VERSION ""

NS_ :

BS_:

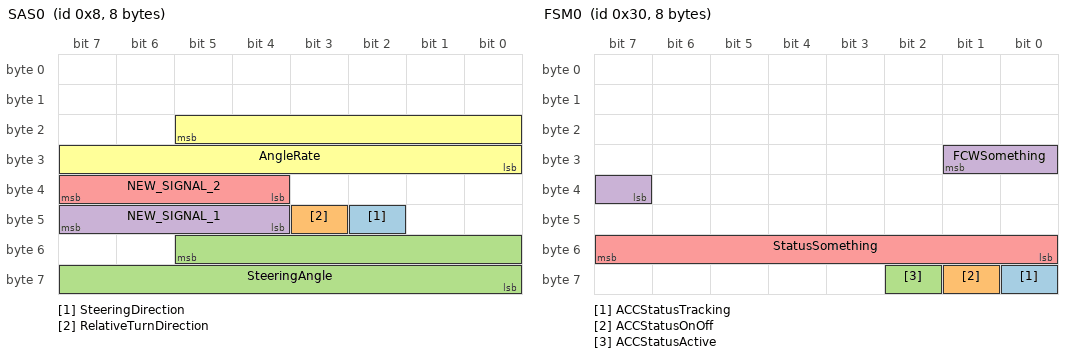
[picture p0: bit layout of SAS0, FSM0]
BO_ 8 SAS0: 8 SAS
 SG_ SteeringDirection : 42|1@0+ (1,0) [0|1] "" XXX
 SG_ RelativeTurnDirection : 43|1@0+ (1,0) [0|1] "" XXX
 SG_ SteeringAngle : 53|14@0+ (0.04395,0) [0|65535] "degrees" XXX
 SG_ NEW_SIGNAL_1 : 47|4@0+ (1,0) [0|15] "" XXX
 SG_ NEW_SIGNAL_2 : 39|4@0+ (1,0) [0|15] "" XXX
 SG_ AngleRate : 21|14@0+ (0.075,0) [0|1500] "deg/S" XXX

BO_ 16 CCButtons: 8 CEM
 SG_ byte0 : 7|8@0+ (1,0) [0|255] "" XXX
 SG_ byte1 : 15|8@0+ (1,0) [0|255] "" XXX
 SG_ byte2 : 23|8@0+ (1,0) [0|255] "" XXX
 SG_ byte3 : 31|8@0+ (1,0) [0|255] "" XXX
 SG_ byte4 : 39|8@0+ (1,0) [0|255] "" XXX
 SG_ byte6 : 55|5@0+ (1,0) [0|31] "" XXX
 SG_ B7b0 : 56|1@0+ (1,0) [0|1] "" XXX
 SG_ B7b1 : 57|1@0+ (1,0) [0|1] "" XXX
 SG_ B7b6 : 62|1@0+ (1,0) [0|1] "" XXX
 SG_ ACCOnOffBtn : 58|1@0+ (1,0) [0|1] "" XXX
 SG_ ACCSetBtn : 63|1@0+ (1,0) [0|1] "" XXX
 SG_ ACCStopBtn : 60|1@0+ (1,0) [0|1] "" XXX
 SG_ ACCResumeBtn : 61|1@0+ (1,0) [0|1] "" XXX
 SG_ ACCMinusBtn : 48|1@0+ (1,0) [0|1] "" XXX
 SG_ TimeGapIncreaseBtn : 49|1@0+ (1,0) [0|1] "" XXX
 SG_ TimeGapDecreaseBtn : 50|1@0+ (1,0) [0|1] "" XXX
 SG_ byte5 : 47|8@0+ (1,0) [0|255] "" XXX
 SG_ B7b3 : 59|1@0+ (1,0) [0|1] "" XXX

BO_ 48 FSM0: 8 FSM
 SG_ ACCStatusTracking : 56|1@0+ (1,0) [0|1] "" XXX
 SG_ ACCStatusOnOff : 57|1@0+ (1,0) [0|1] "" XXX
 SG_ ACCStatusActive : 58|1@0+ (1,0) [0|1] "" XXX
 SG_ FCWSomething : 25|3@0+ (1,0) [0|3] "" XXX
 SG_ StatusSomething : 55|8@0+ (1,0) [0|255] "" XXX

BO_ 64 TCM0: 8 TCM
 SG_ RPMSomething : 42|11@0+ (1,0) [0|2047] "" XXX
 SG_ GearShifter : 46|2@0+ (1,0) [0|3] "" XXX

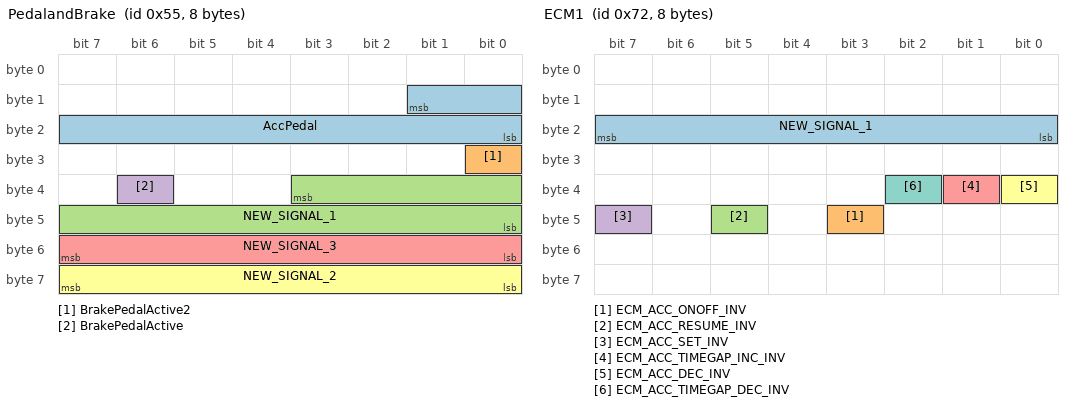
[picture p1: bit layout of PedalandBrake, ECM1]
BO_ 85 PedalandBrake: 8 ECM
 SG_ AccPedal : 9|10@0+ (0.1,0) [0|1023] "%" XXX
 SG_ BrakePedalActive2 : 24|1@0+ (1,0) [0|1] "" XXX
 SG_ NEW_SIGNAL_1 : 35|12@0+ (1,0) [0|4095] "" XXX
 SG_ BrakePedalActive : 38|1@0+ (1,0) [0|1] "" XXX
 SG_ NEW_SIGNAL_3 : 55|8@0+ (1,0) [0|255] "" XXX
 SG_ NEW_SIGNAL_2 : 63|8@0+ (1,0) [0|255] "" XXX

BO_ 101 EngineInfo: 8 XXX
 SG_ NEW_SIGNAL_1 : 17|10@0+ (1,-512) [0|1023] "" XXX
 SG_ EngineSpeed : 52|13@0+ (1,0) [0|1023] "" XXX

BO_ 112 NEW_MSG_4: 8 XXX
 SG_ NEW_SIGNAL_1 : 39|8@0+ (1,0) [0|255] "" XXX

BO_ 114 ECM1: 8 ECM1
 SG_ NEW_SIGNAL_1 : 23|8@0+ (1,0) [0|255] "" XXX
 SG_ ECM_ACC_ONOFF_INV : 43|1@0+ (1,0) [0|1] "" XXX
 SG_ ECM_ACC_RESUME_INV : 45|1@0+ (1,0) [0|1] "" XXX
 SG_ ECM_ACC_SET_INV : 47|1@0+ (1,0) [0|1] "" XXX
 SG_ ECM_ACC_TIMEGAP_INC_INV : 33|1@0+ (1,0) [0|1] "" XXX
 SG_ ECM_ACC_DEC_INV : 32|1@0+ (1,0) [0|1] "" XXX
 SG_ ECM_ACC_TIMEGAP_DEC_INV : 34|1@0+ (1,0) [0|1] "" XXX

BO_ 117 ECM1_2: 8 ECM

BO_ 128 NEW_MSG_5: 8 XXX
 SG_ NEW_SIGNAL_2 : 26|11@0+ (1,0) [0|2047] "" XXX
 SG_ NEW_SIGNAL_1 : 52|13@0+ (1,0) [0|8191] "" XXX

BO_ 176 ECM2: 8 ECM
 SG_ NEW_SIGNAL_1 : 50|11@0+ (1,0) [0|2047] "" XXX
 SG_ NEW_SIGNAL_2 : 47|8@0+ (1,0) [0|63] "" XXX

BO_ 192 Gear: 8 XXX
 SG_ TransmissionGear : 36|3@0+ (1,1) [0|7] "" XXX

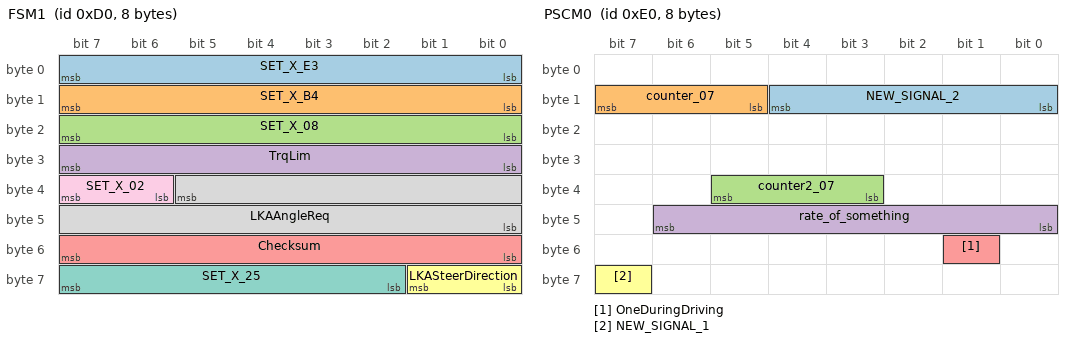
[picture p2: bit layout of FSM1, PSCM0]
BO_ 208 FSM1: 8 FSM
 SG_ SET_X_E3 : 7|8@0+ (1,0) [0|255] "" XXX
 SG_ SET_X_B4 : 15|8@0+ (1,0) [0|255] "" XXX
 SG_ SET_X_08 : 23|8@0+ (1,0) [0|255] "" XXX
 SG_ TrqLim : 31|8@0+ (1,-128) [0|255] "" XXX
 SG_ Checksum : 55|8@0+ (1,0) [0|255] "" XXX
 SG_ LKASteerDirection : 57|2@0+ (1,0) [0|2] "" XXX
 SG_ SET_X_25 : 63|6@0+ (1,0) [0|63] "" XXX
 SG_ LKAAngleReq : 37|14@0+ (0.04395,-360.0384) [-360.0384|359.99445] "degrees" XXX
 SG_ SET_X_02 : 39|2@0+ (1,0) [0|3] "" XXX

BO_ 224 PSCM0: 8 PSCM
 SG_ NEW_SIGNAL_2 : 12|5@0+ (1,0) [0|31] "" XXX
 SG_ counter_07 : 15|3@0+ (1,0) [0|7] "" XXX
 SG_ counter2_07 : 37|3@0+ (1,0) [0|16383] "" XXX
 SG_ rate_of_something : 46|7@0+ (1,0) [0|62] "" XXX
 SG_ OneDuringDriving : 49|1@0+ (1,0) [0|1] "" XXX
 SG_ NEW_SIGNAL_1 : 63|1@0+ (1,0) [0|1] "" XXX

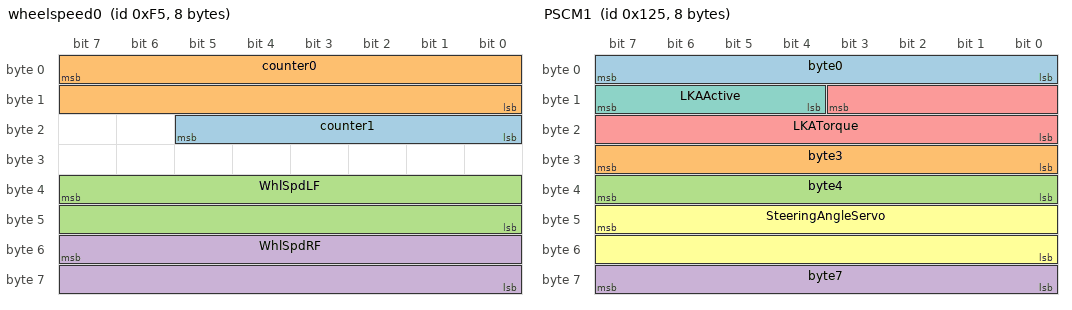
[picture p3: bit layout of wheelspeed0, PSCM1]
BO_ 245 wheelspeed0: 8 BCM
 SG_ counter1 : 21|6@0+ (1,0) [0|65535] "" XXX
 SG_ counter0 : 7|16@0+ (1,0) [0|65535] "" XXX
 SG_ WhlSpdLF : 39|16@0+ (1,0) [0|65535] "" XXX
 SG_ WhlSpdRF : 55|16@0+ (1,0) [0|65535] "" XXX

BO_ 272 SpeedSignal0: 8 XXX
 SG_ VehicleSpeedSignal : 55|16@0+ (0.01,0) [0|65535] "" XXX

BO_ 288 wheel_speed1: 8 BCM
 SG_ WhlSpdLR : 39|16@0+ (1,0) [0|65535] "" XXX
 SG_ WhlSpdRR : 55|16@0+ (1,0) [0|65535] "" XXX

BO_ 293 PSCM1: 8 PSCM
 SG_ byte0 : 7|8@0+ (1,0) [0|255] "" XXX
 SG_ byte3 : 31|8@0+ (1,0) [0|255] "" XXX
 SG_ byte4 : 39|8@0+ (1,0) [0|255] "" XXX
 SG_ byte7 : 63|8@0+ (1,0) [0|255] "" XXX
 SG_ LKATorque : 11|12@0+ (1,-2000) [0|4095] "" XXX
 SG_ SteeringAngleServo : 47|16@0+ (0.04395,-1440.1536) [0|65535] "deg" XXX
 SG_ LKAActive : 15|4@0+ (1,0) [0|15] "" XXX

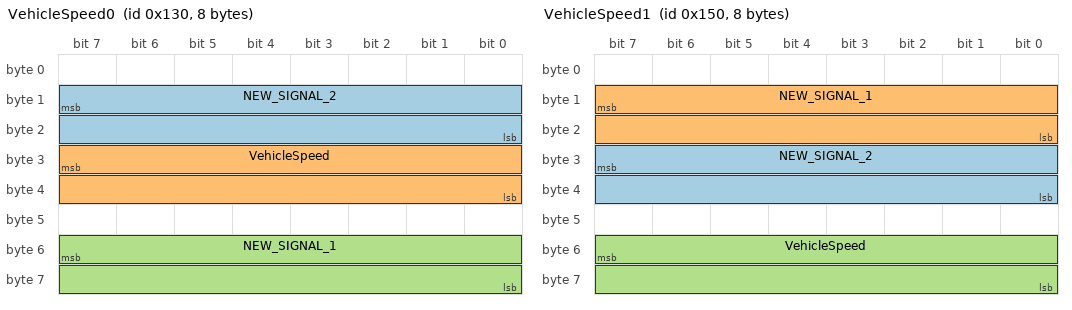
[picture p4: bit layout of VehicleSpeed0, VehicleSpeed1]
BO_ 304 VehicleSpeed0: 8 BCM
 SG_ NEW_SIGNAL_2 : 15|16@0+ (1,0) [0|65535] "" XXX
 SG_ VehicleSpeed : 31|16@0+ (0.01,0) [0|65535] "km/h" XXX
 SG_ NEW_SIGNAL_1 : 55|16@0+ (1,0) [0|65535] "" XXX

BO_ 325 ECM3: 8 ECM

BO_ 336 VehicleSpeed1: 8 BCM
 SG_ NEW_SIGNAL_2 : 31|16@0+ (1,0) [0|65535] "" XXX
 SG_ NEW_SIGNAL_1 : 15|16@0+ (1,0) [0|65535] "" XXX
 SG_ VehicleSpeed : 55|16@0+ (0.01,0) [0|65535] "" XXX

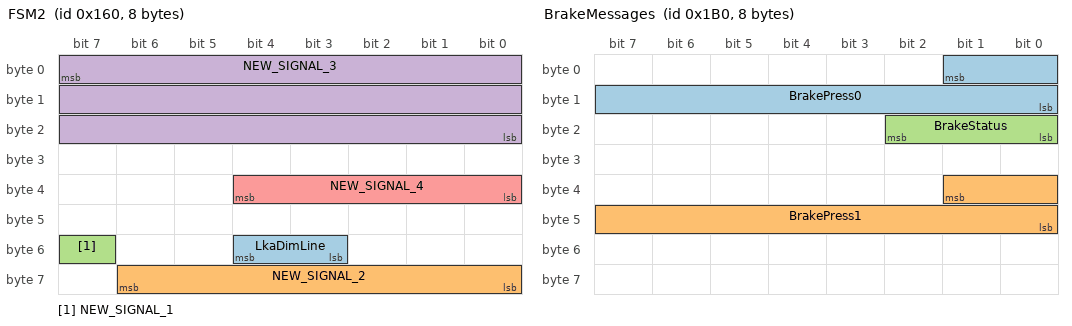
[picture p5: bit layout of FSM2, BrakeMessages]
BO_ 352 FSM2: 8 FSM
 SG_ LkaDimLine : 51|2@1+ (1,0) [0|127] "" XXX
 SG_ NEW_SIGNAL_2 : 56|7@1+ (1,0) [0|255] "" XXX
 SG_ NEW_SIGNAL_1 : 55|1@0+ (1,0) [0|1] "" XXX
 SG_ NEW_SIGNAL_3 : 7|24@0+ (1,0) [0|16777215] "" XXX
 SG_ NEW_SIGNAL_4 : 36|5@0+ (1,0) [0|31] "" XXX

BO_ 432 BrakeMessages: 8 BCM
 SG_ BrakePress0 : 1|10@0+ (1,0) [0|1023] "" XXX
 SG_ BrakePress1 : 33|10@0+ (1,0) [0|1023] "" XXX
 SG_ BrakeStatus : 18|3@0+ (1,0) [0|7] "" XXX

BO_ 464 DIM0: 8 DIM

BO_ 480 BCM0: 8 BCM

BO_ 528 CEM0: 8 CEM

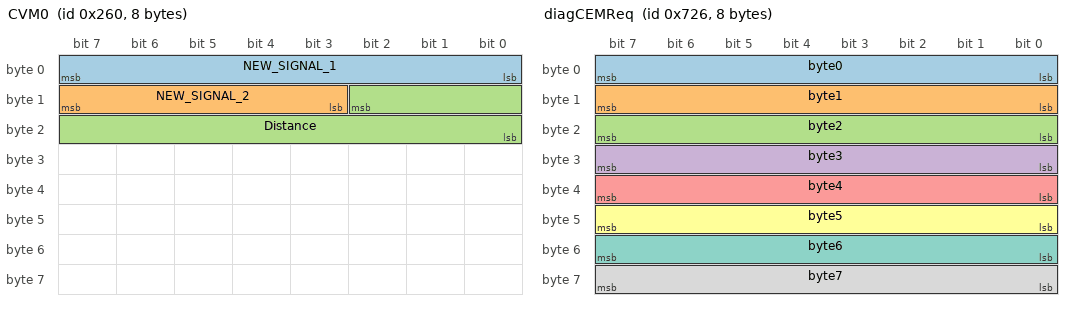
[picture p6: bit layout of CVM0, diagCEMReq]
BO_ 608 CVM0: 8 CVM
 SG_ NEW_SIGNAL_1 : 7|8@0+ (1,0) [0|255] "" XXX
 SG_ NEW_SIGNAL_2 : 15|5@0+ (1,0) [0|32] "" XXX
 SG_ Distance : 10|11@0+ (1,0) [0|2048] "" XXX

BO_ 624 FSM3: 8 FSM
 SG_ NEW_SIGNAL_1 : 23|8@0+ (1,0) [0|255] "" XXX

BO_ 640 FSM4: 8 FSM
 SG_ SpeedTarget : 47|8@0+ (1,0) [0|255] "" XXX
 SG_ NEW_SIGNAL_1 : 49|10@0+ (1,0) [0|255] "" XXX

BO_ 648 SRS0: 8 SRS

BO_ 652 ECM4: 8 ECM

BO_ 656 ECM5: 8 ECM

BO_ 657 ECM6: 8 ECM

BO_ 681 MiscCarInfo: 8 CEM
 SG_ TurnSignal : 1|2@0+ (1,0) [0|3] "" XXX
 SG_ HighBeamOn : 52|1@0+ (1,0) [0|1] "" XX

BO_ 693 ECM7: 8 ECM

BO_ 709 ACC: 8 ECM
 SG_ SpeedTargetACC : 0|9@0+ (0.5,0) [0|511] "" XXX

BO_ 853 FSM5: 8 FSM
 SG_ TargetSpeedOdo : 23|8@0+ (1,0) [0|63] "kph" XXX
 SG_ SpeedSign : 36|5@0+ (5,0) [0|32] "" XXX
 SG_ TextUnderSign : 37|1@0+ (1,0) [0|1] "" XXX
 SG_ NEW_SIGNAL_6 : 39|3@0+ (1,0) [0|3] "" XXX
 SG_ NEW_SIGNAL_5 : 47|8@0+ (1,0) [0|255] "" XXX
 SG_ NEW_SIGNAL_3 : 31|8@0+ (1,0) [0|255] "" XXX
 SG_ LaneMarkingsOdo : 15|4@0+ (1,0) [0|7] "" XXX
 SG_ NEW_SIGNAL_2 : 11|4@0+ (1,0) [0|15] "" XXX
 SG_ NEW_SIGNAL_1 : 7|8@0+ (1,0) [0|255] "" XXX
 SG_ NEW_SIGNAL_4 : 55|16@0+ (1,0) [0|65535] "" XXX

BO_ 864 CEM1: 8 CEM

BO_ 912 DIM1: 8 DIM

BO_ 968 SRS1: 8 SRS
 SG_ PassengerSeatBelt : 22|1@0+ (1,0) [0|1] "" XXX
 SG_ DriverSeatBelt : 19|1@0+ (1,0) [0|1] "" XXX

BO_ 1029 CEMBCM0: 8 CEM

BO_ 1344 NEW_MSG_1: 8 XXX
 SG_ NEW_SIGNAL_1 : 4|13@0+ (1,0) [0|8191] "" XXX

BO_ 1830 diagCEMReq: 8 XXX
 SG_ byte0 : 7|8@0+ (1,0) [0|255] "" XXX
 SG_ byte1 : 15|8@0+ (1,0) [0|255] "" XXX
 SG_ byte2 : 23|8@0+ (1,0) [0|255] "" XXX
 SG_ byte3 : 31|8@0+ (1,0) [0|255] "" XXX
 SG_ byte4 : 39|8@0+ (1,0) [0|255] "" XXX
 SG_ byte5 : 47|8@0+ (1,0) [0|255] "" XXX
 SG_ byte6 : 55|8@0+ (1,0) [0|255] "" XXX
 SG_ byte7 : 63|8@0+ (1,0) [0|255] "" XXX

BO_ 1838 diagCEMResp: 8 XXX
 SG_ byte03 : 7|32@0+ (1,0) [0|4294967295] "" XXX
 SG_ byte47 : 39|32@0+ (1,0) [0|4294967295] "" XXX

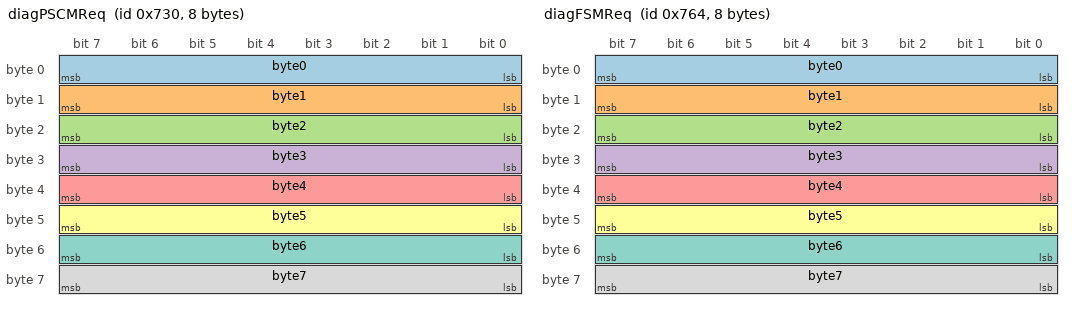
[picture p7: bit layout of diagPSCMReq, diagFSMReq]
BO_ 1840 diagPSCMReq: 8 XXX
 SG_ byte0 : 7|8@0+ (1,0) [0|255] "" XXX
 SG_ byte1 : 15|8@0+ (1,0) [0|255] "" XXX
 SG_ byte2 : 23|8@0+ (1,0) [0|255] "" XXX
 SG_ byte3 : 31|8@0+ (1,0) [0|255] "" XXX
 SG_ byte4 : 39|8@0+ (1,0) [0|255] "" XXX
 SG_ byte5 : 47|8@0+ (1,0) [0|255] "" XXX
 SG_ byte6 : 55|8@0+ (1,0) [0|255] "" XXX
 SG_ byte7 : 63|8@0+ (1,0) [0|255] "" XXX

BO_ 1848 diagPSCMResp: 8 XXX
 SG_ byte03 : 7|32@0+ (1,0) [0|4294967295] "" XXX
 SG_ byte47 : 39|32@0+ (1,0) [0|4294967295] "" XXX

BO_ 1892 diagFSMReq: 8 XXX
 SG_ byte0 : 7|8@0+ (1,0) [0|255] "" XXX
 SG_ byte1 : 15|8@0+ (1,0) [0|255] "" XXX
 SG_ byte2 : 23|8@0+ (1,0) [0|255] "" XXX
 SG_ byte3 : 31|8@0+ (1,0) [0|255] "" XXX
 SG_ byte4 : 39|8@0+ (1,0) [0|255] "" XXX
 SG_ byte5 : 47|8@0+ (1,0) [0|255] "" XXX
 SG_ byte6 : 55|8@0+ (1,0) [0|255] "" XXX
 SG_ byte7 : 63|8@0+ (1,0) [0|255] "" XXX

BO_ 1900 diagFSMResp: 8 XXX
 SG_ byte03 : 7|32@0+ (1,0) [0|4294967295] "" XXX
 SG_ byte47 : 39|32@0+ (1,0) [0|4294967295] "" XXX

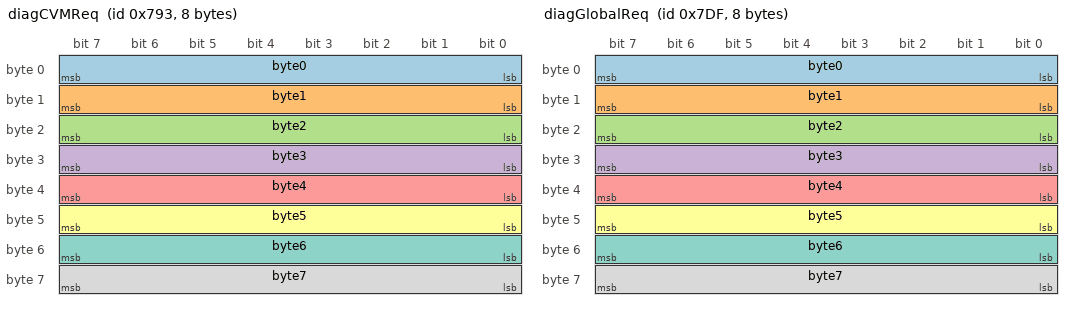
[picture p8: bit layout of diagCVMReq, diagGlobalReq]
BO_ 1939 diagCVMReq: 8 XXX
 SG_ byte0 : 7|8@0+ (1,0) [0|255] "" XXX
 SG_ byte1 : 15|8@0+ (1,0) [0|255] "" XXX
 SG_ byte2 : 23|8@0+ (1,0) [0|255] "" XXX
 SG_ byte3 : 31|8@0+ (1,0) [0|255] "" XXX
 SG_ byte4 : 39|8@0+ (1,0) [0|255] "" XXX
 SG_ byte5 : 47|8@0+ (1,0) [0|255] "" XXX
 SG_ byte6 : 55|8@0+ (1,0) [0|255] "" XXX
 SG_ byte7 : 63|8@0+ (1,0) [0|255] "" XXX

BO_ 1947 diagCVMResp: 8 XXX
 SG_ byte03 : 7|32@0+ (1,0) [0|4294967295] "" XXX
 SG_ byte47 : 39|32@0+ (1,0) [0|4294967295] "" XXX

BO_ 2015 diagGlobalReq: 8 XXX
 SG_ byte0 : 7|8@0+ (1,0) [0|255] "" XXX
 SG_ byte1 : 15|8@0+ (1,0) [0|255] "" XXX
 SG_ byte2 : 23|8@0+ (1,0) [0|255] "" XXX
 SG_ byte3 : 31|8@0+ (1,0) [0|255] "" XXX
 SG_ byte4 : 39|8@0+ (1,0) [0|255] "" XXX
 SG_ byte5 : 47|8@0+ (1,0) [0|255] "" XXX
 SG_ byte6 : 55|8@0+ (1,0) [0|255] "" XXX
 SG_ byte7 : 63|8@0+ (1,0) [0|255] "" XXX

BU_: K109_FCM B233B_LRR NEO VIS_FO VIS2_FO K124_ASCM Vector__XXX EOCM_F_FO EOCM2A_IMX6_FO EOCM2A_K2_FO EOCM2A_K1_FO EOCM2B_IMX6_FO EOCM2B_K2_FO EOCM2B_K1_FO
VAL_TABLE_ RangeMode 1 "Active" 0 "Inactive" ;
VAL_TABLE_ TrkConf 3 "Confident" 2 "Speculative" 1 "Highly speculative" 0 "Invalid" ;
VAL_TABLE_ TrkMeasStatus 3 "Measured current cycle" 2 "Latent track not detected" 1 "New object" 0 "No object" ;
VAL_TABLE_ TrkDynProp 4 "Moving in opposite direction" 3 "Moving in same direction" 2 "Has moved but currently stopped" 1 "Has never moved," 0 "Unknown" ;
VAL_TABLE_ FrntVsnInPthVehBrkNwSt 10 "Active" 5 "Inactive" ;
VAL_TABLE_ FrntVsnClostPedBrkNwSt 10 "Active" 5 "Inactive" ;
VAL_TABLE_ LaneSnsLLnPosValid 1 "Invalid" 0 "Valid" ;
VAL_TABLE_ LnSnsRLnPosValid 1 "Invalid" 0 "Valid" ;
VAL_TABLE_ ObjectType 7 "no object present" 6 "fixed roadside object" 5 "fixed overhead object" 4 "pedestrian" 3 "motocycle  / bicycle" 2 "Large vehicle (semi)" 1 "4 Wheel Vehicle (car, small trk)" 0 "Unknown" ;
VAL_TABLE_ FwVsnCinCoutPotT9Rev 2 "Right" 1 "Left" 0 "None" ;
VAL_TABLE_ FwVsnCinCoutPotT8Rev 2 "Right" 1 "Left" 0 "None" ;
VAL_TABLE_ FwVsnCinCoutPotT7Rev 2 "Right" 1 "Left" 0 "None" ;
VAL_TABLE_ FwVsnCinCoutPotT6Rev 2 "Right" 1 "Left" 0 "None" ;
VAL_TABLE_ FwVsnCinCoutPotT5Rev 2 "Right" 1 "Left" 0 "None" ;
VAL_TABLE_ FwVsnCinCoutPotT4Rev 2 "Right" 1 "Left" 0 "None" ;
VAL_TABLE_ FwVsnCinCoutPotT3Rev 2 "Right" 1 "Left" 0 "None" ;
VAL_TABLE_ FwVsnCinCoutPotT2Rev 2 "Right" 1 "Left" 0 "None" ;
VAL_TABLE_ FwVsnCinCoutPotT1Rev 2 "Right" 1 "Left" 0 "None" ;
VAL_TABLE_ FwVsnCinCoutPotT12Rev 2 "Right" 1 "Left" 0 "None" ;
VAL_TABLE_ FwVsnCinCoutPotT11Rev 2 "Right" 1 "Left" 0 "None" ;
VAL_TABLE_ FwVsnCinCoutPotT10Rev 2 "Right" 1 "Left" 0 "None" ;

CM_ BU_ K182_PACM "Parking Assist Control Module";
CM_ BU_ K43_PSCM "Power Steering Control Module";
CM_ BU_ K17_EBCM "Electronic Brake Control Module";
CM_ BU_ NEO "Comma NEO";
CM_ BU_ K124_ASCM "Active Safety Control Module";
BA_DEF_  "UseGMParameterIDs" INT 0 0;
BA_DEF_  "ProtocolType" STRING ;
BA_DEF_  "BusType" STRING ;
BA_DEF_DEF_  "UseGMParameterIDs" 1;
BA_DEF_DEF_  "ProtocolType" "GMLAN";
BA_DEF_DEF_  "BusType" "";
BA_ "UseGMParameterIDs" 0;
BA_ "BusType" "CAN";

VAL_ 295 GEAR 0 "P" 1 "R" 2 "N" 3 "D" 4 "B" ;
VAL_ 466 CRUISE_STATE 11 "timer_3sec" 10 "setspeeddown" 9 "setspeedup" 8 "active" 7 "standstill" 1 "off" 0 "off";
VAL_ 610 STATE 5 "override" 3 "enabled" 1 "disabled" ;
VAL_ 610 LKA_STATE 50 "temporary_fault" ;
VAL_ 614 STATE 3 "enabled" 1 "disabled" ;
VAL_ 614 DIRECTION_CMD 3 "right" 2 "center" 1 "left" ;
VAL_ 1556 TURN_SIGNALS 3 "none" 2 "right" 1 "left" ;
VAL_ 467 LOW_SPEED_LOCKOUT 2 "low speed locked" 1 "ok" ;
VAL_ 921 CRUISE_CONTROL_STATE 2 "disabled" 11 "hold" 10 "hold_waiting_user_cmd" 6 "enabled" 5 "faulted" ;
VAL_ 1042 BARRIERS 3 "both" 2 "right" 1 "left" 0 "none" ;
VAL_ 1042 RIGHT_LINE 3 "orange" 2 "double" 1 "solid" 0 "none" ;
VAL_ 1042 LEFT_LINE 3 "orange" 2 "double" 1 "solid" 0 "none" ;
VAL_ 1042 LDA_ALERT 3 "hold with continuous beep" 2 "LDA unavailable" 1 "hold" 0 "none" ;
